# STM32WL5x_CM0P register map
File version: 1.9
CPU: CM0 r0p1, little endian, MPU, no FPU, 4 interrupt priority bits
Registers are 32-bit, read-write, reset 0x0 unless marked. A register's access mark holds for its fields unless they carry their own. Offsets are from the block's base; [hi:lo] are bit positions; {n}, {i} and the like mark numbered series; 'fields as' and 'values as' point back to an identical list.

## EXTI — External interrupt/event controller
Base 0x58000800
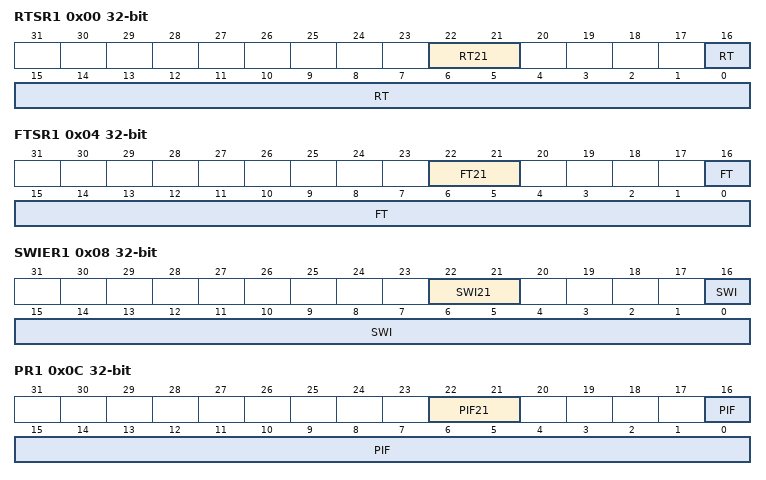
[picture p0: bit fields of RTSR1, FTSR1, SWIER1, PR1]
0x00 RTSR1 — rising trigger selection register
  [22:21] RT21 — Rising trigger event configuration bit of Configurable Event input
  [16:0] RT — Rising trigger event configuration bit of Configurable Event input
0x04 FTSR1 — falling trigger selection register
  [22:21] FT21 — Falling trigger event configuration bit of Configurable Event input
  [16:0] FT — Falling trigger event configuration bit of Configurable Event input
0x08 SWIER1 — software interrupt event register
  [22:21] SWI21 — Software interrupt on event
  [16:0] SWI — Software interrupt on event
0x0C PR1 — EXTI pending register
  [22:21] PIF21 — Configurable event inputs Pending bit
  [16:0] PIF — Configurable event inputs Pending bit
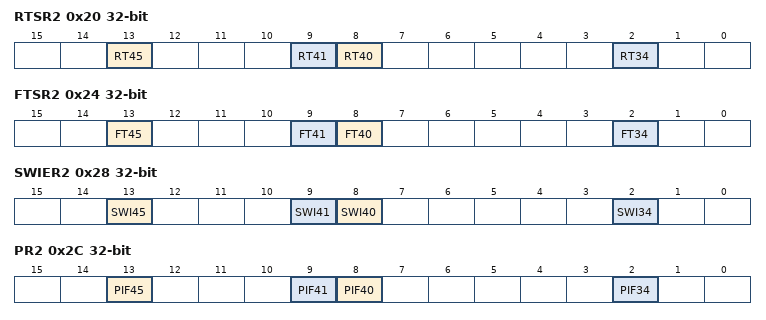
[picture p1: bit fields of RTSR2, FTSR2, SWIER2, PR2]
0x20 RTSR2 — rising trigger selection register
  [13] RT45 — Rising trigger event configuration bit of Configurable Event input
  [9] RT41 — Rising trigger event configuration bit of Configurable Event input
  [8] RT40 — Rising trigger event configuration bit of Configurable Event input
  [2] RT34 — Rising trigger event configuration bit of Configurable Event input
0x24 FTSR2 — falling trigger selection register
  [13] FT45 — Falling trigger event configuration bit of Configurable Event input
  [9] FT41 — Falling trigger event configuration bit of Configurable Event input
  [8] FT40 — Falling trigger event configuration bit of Configurable Event input
  [2] FT34 — Falling trigger event configuration bit of Configurable Event input
0x28 SWIER2 — software interrupt event register
  [13] SWI45 — Software interrupt on event 45
  [9] SWI41 — Software interrupt on event
  [8] SWI40 — Software interrupt on event
  [2] SWI34 — Software interrupt on event
0x2C PR2 — pending register
  [13] PIF45 — Configurable event inputs 45 Pending bit.
  [9] PIF41 — Configurable event inputs 40_41 Pending bit.
  [8] PIF40 — Configurable event inputs 40_41 Pending bit.
  [2] PIF34 — Configurable event inputs 33 Pending bit.
0x80 C1IMR1 — interrupt mask register
  [31:0] IM — wakeup with interrupt Mask on event input
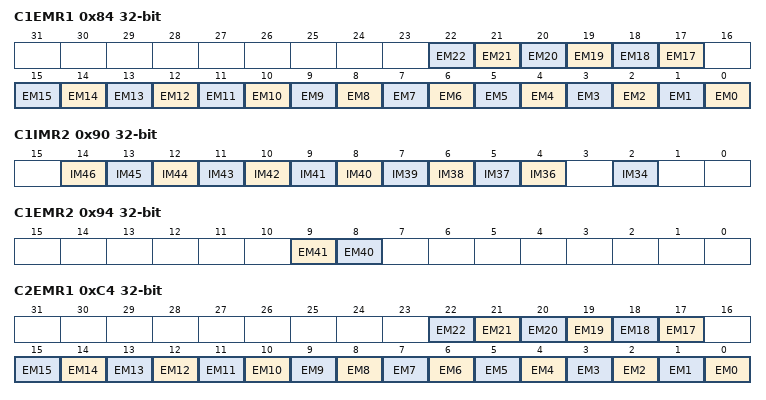
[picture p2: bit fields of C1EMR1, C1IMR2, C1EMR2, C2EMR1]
0x84 C1EMR1 — event mask register
  [n] EM{n} (n=17..22) — Wakeup with event generation Mask on Event input
  [n] EM{n} (n=0..15) — Wakeup with event generation Mask on Event input
0x90 C1IMR2 — wakeup with interrupt mask register
  [n-32] IM{n} (n=36..46) — wakeup with interrupt mask on event input
  [2] IM34 — wakeup with interrupt mask on event input
0x94 C1EMR2 — wakeup with event mask register
  [9] EM41 — Wakeup with event generation Mask on Event input
  [8] EM40 — Wakeup with event generation Mask on Event input
0xC0 C2IMR1 — interrupt mask register
  [31:0] IM — wakeup with interrupt Mask on Event input
0xC4 C2EMR1 — event mask register
  fields as C1EMR1
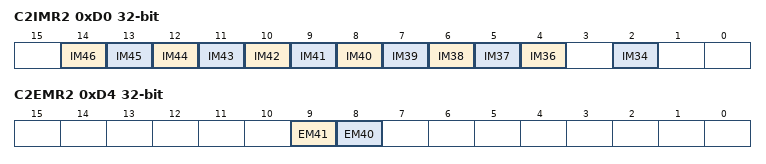
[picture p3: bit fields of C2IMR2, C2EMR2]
0xD0 C2IMR2 — wakeup with interrupt mask register
  fields as C1IMR2
0xD4 C2EMR2 — wakeup with event mask register
  fields as C1EMR2

## GPIOA — General-purpose I/Os
Base 0x48000000
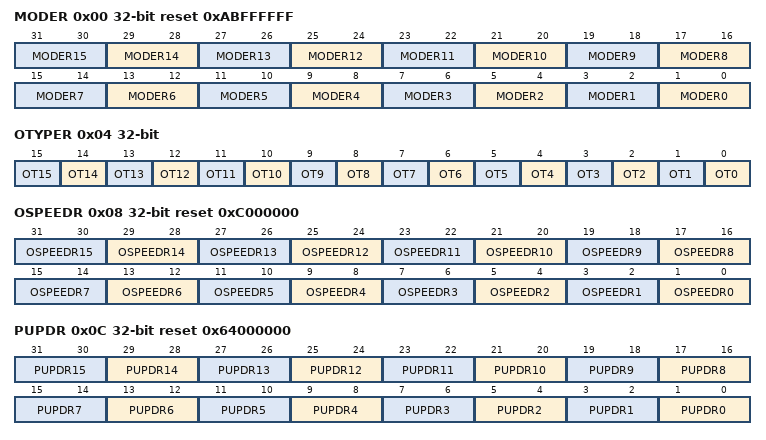
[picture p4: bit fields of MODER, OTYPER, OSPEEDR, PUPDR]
0x00 MODER reset 0xABFFFFFF — GPIO port mode register
  [2n+1:2n] MODER{n} (n=0..15)
0x04 OTYPER — GPIO port output type register
  [n] OT{n} (n=0..15) — Port x configuration bits (y = 0..15)
0x08 OSPEEDR reset 0xC000000 — GPIO port output speed register
  [2n+1:2n] OSPEEDR{n} (n=0..15) — Port x configuration bits (y = 0..15)
0x0C PUPDR reset 0x64000000 — GPIO port pull-up/pull-down register
  [2n+1:2n] PUPDR{n} (n=0..15) — Port x configuration bits (y = 0..15)
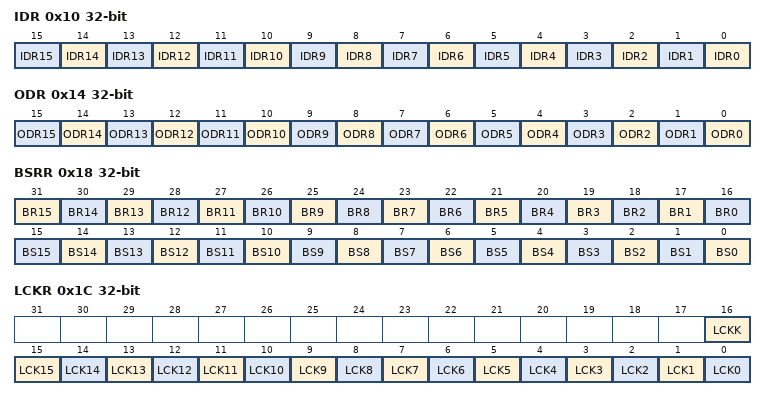
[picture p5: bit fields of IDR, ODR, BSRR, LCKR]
0x10 IDR ro — GPIO port input data register
  [n] IDR{n} (n=0..15) — Port input data (y = 0..15)
0x14 ODR — GPIO port output data register
  [n] ODR{n} (n=0..15) — Port output data (y = 0..15)
0x18 BSRR wo — GPIO port bit set/reset register
  [n+16] BR{n} (n=1..15) — Port x reset bit y (y = 0..15)
  [16] BR0 — Port x set bit y (y= 0..15)
  [n] BS{n} (n=0..15) — Port x set bit y (y= 0..15)
0x1C LCKR — GPIO port configuration lock register
  [16] LCKK — Port x lock bit y (y= 0..15)
  [n] LCK{n} (n=0..15) — Port x lock bit y (y= 0..15)
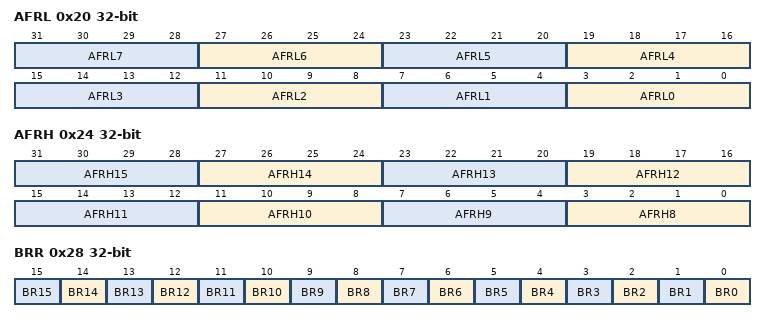
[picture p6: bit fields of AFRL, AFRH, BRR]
0x20 AFRL — GPIO alternate function low register
  [4n+3:4n] AFRL{n} (n=0..7) — Alternate function selection for port x bit y (y = 0..7)
0x24 AFRH — GPIO alternate function high register
  [4n-29:4n-32] AFRH{n} (n=8..15) — Alternate function selection for port x bit y (y = 8..15)
0x28 BRR — GPIO port bit reset register
  [n] BR{n} (n=0..15) — Port Reset bit

## GPIOB — General-purpose I/Os
Base 0x48000400
Registers as GPIOA; these are added or differ:
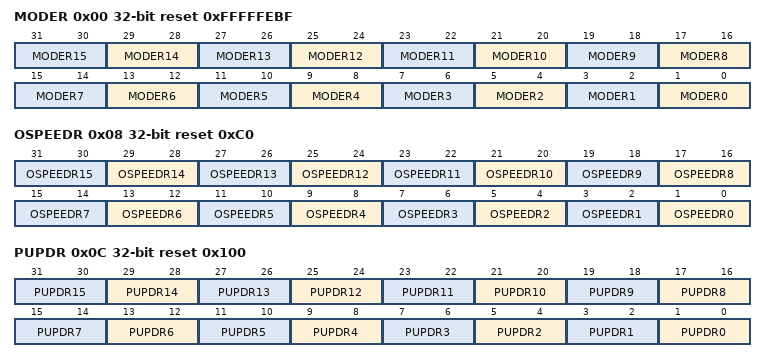
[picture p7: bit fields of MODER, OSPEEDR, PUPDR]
0x00 MODER reset 0xFFFFFEBF — GPIO port mode register
  [2n+1:2n] MODER{n} (n=0..15) — Port x configuration bits (y = 0..15)
0x08 OSPEEDR reset 0xC0 — GPIO port output speed register
  [2n+1:2n] OSPEEDR{n} (n=0..15) — Port x configuration bits (y = 0..15)
0x0C PUPDR reset 0x100 — GPIO port pull-up/pull-down register
  [2n+1:2n] PUPDR{n} (n=0..15) — Port x configuration bits (y = 0..15)
